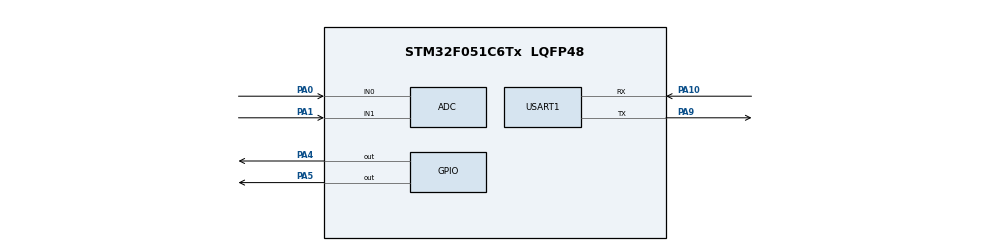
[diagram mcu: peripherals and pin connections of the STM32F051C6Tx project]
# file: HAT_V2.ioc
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Mcu.Family=STM32F0
Mcu.Name=STM32F051C6Tx
Mcu.Package=LQFP48
PA0.Mode=IN0
PA0.Signal=ADC_IN0
PA1.Mode=IN1
PA1.Signal=ADC_IN1
PA10.Mode=Asynchronous
PA10.Signal=USART1_RX
PA4.PinState=GPIO_PIN_SET
PA4.Signal=GPIO_Output
PA5.PinState=GPIO_PIN_SET
PA5.Signal=GPIO_Output
PA9.Mode=Asynchronous
PA9.Signal=USART1_TX
ProjectManager.HeapSize=0x200
ProjectManager.StackSize=0x400
ProjectManager.TargetToolchain=EWARM V8.32
RCC.APB1CLKDivider=RCC_HCLK_DIV2
RCC.APB1Freq_Value=4000000
RCC.APB1TimFreq_Value=8000000
USART1.VirtualMode-Asynchronous=VM_ASYNC
VP_TIM1_VS_ClockSourceITR.Mode=TriggerSource_ITR0
VP_TIM1_VS_ControllerModeReset.Mode=Reset Mode
board=custom

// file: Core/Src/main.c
/* USER CODE BEGIN Header */
/**
  ******************************************************************************
  * @file           : main.c
  * @brief          : Main program body
  ******************************************************************************
  * @attention
  *
  * Copyright (c) 2023 STMicroelectronics.
  * All rights reserved.
  *
  * This software is licensed under terms that can be found in the LICENSE file
  * in the root directory of this software component.
  * If no LICENSE file comes with this software, it is provided AS-IS.
  *
  ******************************************************************************
  */
/* USER CODE END Header */
#include "main.h"

ADC_HandleTypeDef hadc;

TIM_HandleTypeDef htim1;

UART_HandleTypeDef huart1;

void SystemClock_Config(void);
static void MX_GPIO_Init(void);
static void MX_USART1_UART_Init(void);
static void MX_ADC_Init(void);
static void MX_TIM1_Init(void);

int main(void)
{

  /* MCU Configuration--------------------------------------------------------*/

  /* Reset of all peripherals, Initializes the Flash interface and the Systick. */
  HAL_Init();

  /* Configure the system clock */
  SystemClock_Config();

  /* Initialize all configured peripherals */
  MX_GPIO_Init();
  MX_USART1_UART_Init();
  MX_ADC_Init();
  MX_TIM1_Init();

  /* Infinite loop */
  while (1)
  {

    /* USER CODE BEGIN 3 */
	  char UART1_rxBuffer[12];
	  sprintf(UART1_rxBuffer, "Hello HAT\n");
  }
  /* USER CODE END 3 */
}

void SystemClock_Config(void)
{
  RCC_OscInitTypeDef RCC_OscInitStruct = {0};
  RCC_ClkInitTypeDef RCC_ClkInitStruct = {0};
  RCC_PeriphCLKInitTypeDef PeriphClkInit = {0};

  /** Initializes the RCC Oscillators according to the specified parameters
  * in the RCC_OscInitTypeDef structure.
  */
  RCC_OscInitStruct.OscillatorType = RCC_OSCILLATORTYPE_HSI|RCC_OSCILLATORTYPE_HSI14;
  RCC_OscInitStruct.HSIState = RCC_HSI_ON;
  RCC_OscInitStruct.HSI14State = RCC_HSI14_ON;
  RCC_OscInitStruct.HSICalibrationValue = RCC_HSICALIBRATION_DEFAULT;
  RCC_OscInitStruct.HSI14CalibrationValue = 16;
  RCC_OscInitStruct.PLL.PLLState = RCC_PLL_NONE;
  if (HAL_RCC_OscConfig(&RCC_OscInitStruct) != HAL_OK)
  {
    Error_Handler();
  }

  /** Initializes the CPU, AHB and APB buses clocks
  */
  RCC_ClkInitStruct.ClockType = RCC_CLOCKTYPE_HCLK|RCC_CLOCKTYPE_SYSCLK
                              |RCC_CLOCKTYPE_PCLK1;
  RCC_ClkInitStruct.SYSCLKSource = RCC_SYSCLKSOURCE_HSI;
  RCC_ClkInitStruct.AHBCLKDivider = RCC_SYSCLK_DIV1;
  RCC_ClkInitStruct.APB1CLKDivider = RCC_HCLK_DIV2;

  if (HAL_RCC_ClockConfig(&RCC_ClkInitStruct, FLASH_LATENCY_0) != HAL_OK)
  {
    Error_Handler();
  }
  PeriphClkInit.PeriphClockSelection = RCC_PERIPHCLK_USART1;
  PeriphClkInit.Usart1ClockSelection = RCC_USART1CLKSOURCE_PCLK1;
  if (HAL_RCCEx_PeriphCLKConfig(&PeriphClkInit) != HAL_OK)
  {
    Error_Handler();
  }
}

static void MX_ADC_Init(void)
{

  ADC_ChannelConfTypeDef sConfig = {0};

  /** Configure the global features of the ADC (Clock, Resolution, Data Alignment and number of conversion)
  */
  hadc.Instance = ADC1;
  hadc.Init.ClockPrescaler = ADC_CLOCK_ASYNC_DIV1;
  hadc.Init.Resolution = ADC_RESOLUTION_12B;
  hadc.Init.DataAlign = ADC_DATAALIGN_RIGHT;
  hadc.Init.ScanConvMode = ADC_SCAN_DIRECTION_FORWARD;
  hadc.Init.EOCSelection = ADC_EOC_SINGLE_CONV;
  hadc.Init.LowPowerAutoWait = DISABLE;
  hadc.Init.LowPowerAutoPowerOff = DISABLE;
  hadc.Init.ContinuousConvMode = DISABLE;
  hadc.Init.DiscontinuousConvMode = DISABLE;
  hadc.Init.ExternalTrigConv = ADC_SOFTWARE_START;
  hadc.Init.ExternalTrigConvEdge = ADC_EXTERNALTRIGCONVEDGE_NONE;
  hadc.Init.DMAContinuousRequests = DISABLE;
  hadc.Init.Overrun = ADC_OVR_DATA_PRESERVED;
  if (HAL_ADC_Init(&hadc) != HAL_OK)
  {
    Error_Handler();
  }

  /** Configure for the selected ADC regular channel to be converted.
  */
  sConfig.Channel = ADC_CHANNEL_0;
  sConfig.Rank = ADC_RANK_CHANNEL_NUMBER;
  sConfig.SamplingTime = ADC_SAMPLETIME_1CYCLE_5;
  if (HAL_ADC_ConfigChannel(&hadc, &sConfig) != HAL_OK)
  {
    Error_Handler();
  }

  /** Configure for the selected ADC regular channel to be converted.
  */
  sConfig.Channel = ADC_CHANNEL_1;
  if (HAL_ADC_ConfigChannel(&hadc, &sConfig) != HAL_OK)
  {
    Error_Handler();
  }

}

static void MX_TIM1_Init(void)
{

  TIM_SlaveConfigTypeDef sSlaveConfig = {0};
  TIM_MasterConfigTypeDef sMasterConfig = {0};

  htim1.Instance = TIM1;
  htim1.Init.Prescaler = 0;
  htim1.Init.CounterMode = TIM_COUNTERMODE_UP;
  htim1.Init.Period = 65535;
  htim1.Init.ClockDivision = TIM_CLOCKDIVISION_DIV1;
  htim1.Init.RepetitionCounter = 0;
  htim1.Init.AutoReloadPreload = TIM_AUTORELOAD_PRELOAD_DISABLE;
  if (HAL_TIM_Base_Init(&htim1) != HAL_OK)
  {
    Error_Handler();
  }
  sSlaveConfig.SlaveMode = TIM_SLAVEMODE_RESET;
  sSlaveConfig.InputTrigger = TIM_TS_ITR0;
  if (HAL_TIM_SlaveConfigSynchro(&htim1, &sSlaveConfig) != HAL_OK)
  {
    Error_Handler();
  }
  sMasterConfig.MasterOutputTrigger = TIM_TRGO_RESET;
  sMasterConfig.MasterSlaveMode = TIM_MASTERSLAVEMODE_DISABLE;
  if (HAL_TIMEx_MasterConfigSynchronization(&htim1, &sMasterConfig) != HAL_OK)
  {
    Error_Handler();
  }

}

static void MX_USART1_UART_Init(void)
{

  huart1.Instance = USART1;
  huart1.Init.BaudRate = 38400;
  huart1.Init.WordLength = UART_WORDLENGTH_8B;
  huart1.Init.StopBits = UART_STOPBITS_1;
  huart1.Init.Parity = UART_PARITY_NONE;
  huart1.Init.Mode = UART_MODE_TX_RX;
  huart1.Init.HwFlowCtl = UART_HWCONTROL_NONE;
  huart1.Init.OverSampling = UART_OVERSAMPLING_16;
  huart1.Init.OneBitSampling = UART_ONE_BIT_SAMPLE_DISABLE;
  huart1.AdvancedInit.AdvFeatureInit = UART_ADVFEATURE_NO_INIT;
  if (HAL_UART_Init(&huart1) != HAL_OK)
  {
    Error_Handler();
  }

}

static void MX_GPIO_Init(void)
{
  GPIO_InitTypeDef GPIO_InitStruct = {0};

  /* GPIO Ports Clock Enable */
  __HAL_RCC_GPIOA_CLK_ENABLE();

  /*Configure GPIO pin Output Level */
  HAL_GPIO_WritePin(GPIOA, GPIO_PIN_4|GPIO_PIN_5, GPIO_PIN_SET);

  /*Configure GPIO pins : PA4 PA5 */
  GPIO_InitStruct.Pin = GPIO_PIN_4|GPIO_PIN_5;
  GPIO_InitStruct.Mode = GPIO_MODE_OUTPUT_PP;
  GPIO_InitStruct.Pull = GPIO_NOPULL;
  GPIO_InitStruct.Speed = GPIO_SPEED_FREQ_LOW;
  HAL_GPIO_Init(GPIOA, &GPIO_InitStruct);

}

void Error_Handler(void)
{
  __disable_irq();
  while (1)
  {
  }
}
